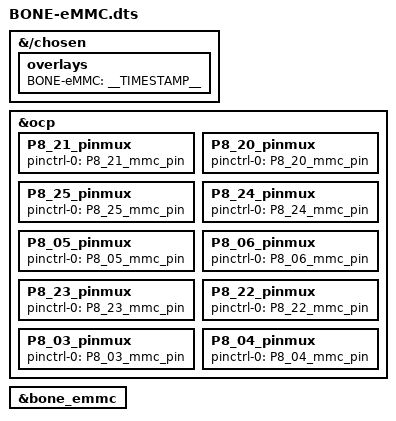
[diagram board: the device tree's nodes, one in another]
/*
 * Copyright (C) 2020 Deepak Khatri <deepaklorkhatri7@gmail.com>
 * See Cape Interface Spec page for more info on Bone Buses
 * https://elinux.org/Beagleboard:BeagleBone_cape_interface_spec
 *
 * Virtual cape for Bone eMMC (BBBWL/BBB/BBAI)
 *
 * This program is free software; you can redistribute it and/or modify
 * it under the terms of the GNU General Public License version 2 as
 * published by the Free Software Foundation.
 */

/dts-v1/;
/plugin/;

/*
* Helper to show loaded overlays under: /proc/device-tree/chosen/overlays/
*/
&{/chosen} {
    overlays {
        BONE-eMMC = __TIMESTAMP__;
    };
};

/*
 * Update the default pinmux of the pins.
 * See these files for the phandles (&P9_* & &P8_*)
 * BeagleBoard-DeviceTrees/v4.19.x-ti-overlays/src/arm/am335x-bone-common-univ.dtsi
 * BeagleBoard-DeviceTrees/v4.19.x-ti-overlays/src/arm/am572x-bone-common-univ.dtsi
 */
&ocp {
	P8_21_pinmux { pinctrl-0 = <&P8_21_mmc_pin>; };	/* eMMC_clk */
	P8_20_pinmux { pinctrl-0 = <&P8_20_mmc_pin>; };	/* eMMC_cmd */
	P8_25_pinmux { pinctrl-0 = <&P8_25_mmc_pin>; };	/* eMMC_dat0 */
	P8_24_pinmux { pinctrl-0 = <&P8_24_mmc_pin>; };	/* eMMC_dat1 */
	P8_05_pinmux { pinctrl-0 = <&P8_05_mmc_pin>; };	/* eMMC_dat2 */
	P8_06_pinmux { pinctrl-0 = <&P8_06_mmc_pin>; };	/* eMMC_dat3 */
	P8_23_pinmux { pinctrl-0 = <&P8_23_mmc_pin>; };	/* eMMC_dat4 */
	P8_22_pinmux { pinctrl-0 = <&P8_22_mmc_pin>; };	/* eMMC_dat5 */
	P8_03_pinmux { pinctrl-0 = <&P8_03_mmc_pin>; };	/* eMMC_dat6 */
	P8_04_pinmux { pinctrl-0 = <&P8_04_mmc_pin>; };	/* eMMC_dat7 */
};

/*
 * See these files for the phandles (&bone_*) and other bone bus nodes
 * BeagleBoard-DeviceTrees/v4.19.x-ti-overlays/src/arm/bbai-bone-buses.dtsi
 * BeagleBoard-DeviceTrees/v4.19.x-ti-overlays/src/arm/bbb-bone-buses.dtsi
 */

&bone_emmc {
	status = "okay";
};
